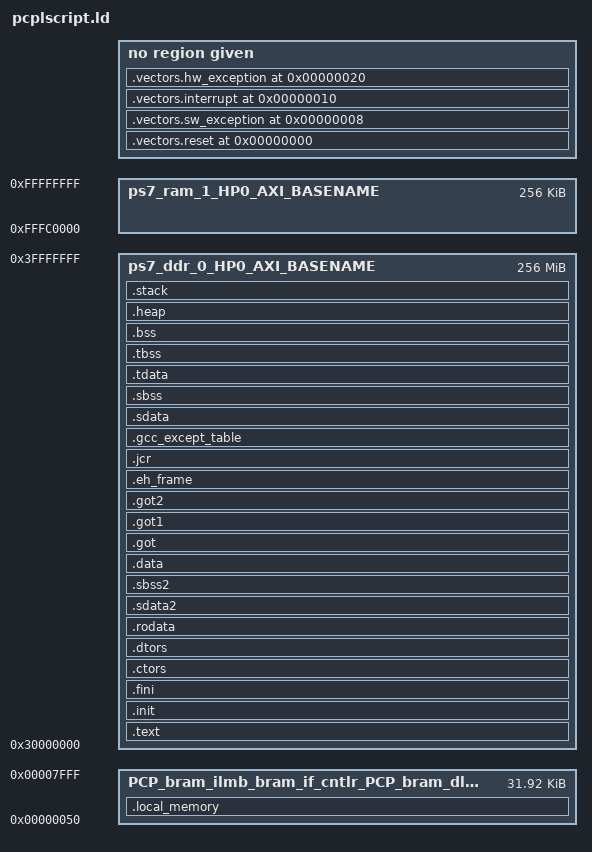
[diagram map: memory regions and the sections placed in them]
/*******************************************************************/
/*                                                                 */
/* This file is automatically generated by linker script generator.*/
/*                                                                 */
/* Version: Xilinx Software developement kit 2016.2                */
/*                                                                 */
/* Copyright (c) 2010-2016 Xilinx, Inc.  All rights reserved.      */
/*                                                                 */
/* Description : MicroBlaze Linker Script                          */
/*                                                                 */
/*******************************************************************/

_STACK_SIZE = DEFINED(_STACK_SIZE) ? _STACK_SIZE : 0xA00000;
_HEAP_SIZE = DEFINED(_HEAP_SIZE) ? _HEAP_SIZE : 0xA00000;

/* Define Memories in the system */

MEMORY
{
   PCP_bram_ilmb_bram_if_cntlr_PCP_bram_dlmb_bram_if_cntlr : ORIGIN = 0x50, LENGTH = 0x7FB0
   ps7_ddr_0_HP0_AXI_BASENAME : ORIGIN = 0x30000000, LENGTH = 0x10000000
   ps7_ram_1_HP0_AXI_BASENAME : ORIGIN = 0xFFFC0000, LENGTH = 0x40000
}

/* Specify the default entry point to the program */

ENTRY(_start)

/* Define the sections, and where they are mapped in memory */

SECTIONS
{
.vectors.reset 0x0 : {
   KEEP (*(.vectors.reset))
}

.vectors.sw_exception 0x8 : {
   KEEP (*(.vectors.sw_exception))
}

.vectors.interrupt 0x10 : {
   KEEP (*(.vectors.interrupt))
}

.vectors.hw_exception 0x20 : {
   KEEP (*(.vectors.hw_exception))
}

.text : {
   *(.text)
   *(.text.*)
   *(.gnu.linkonce.t.*)
} > ps7_ddr_0_HP0_AXI_BASENAME

.init : {
   KEEP (*(.init))
} > ps7_ddr_0_HP0_AXI_BASENAME

.fini : {
   KEEP (*(.fini))
} > ps7_ddr_0_HP0_AXI_BASENAME

.ctors : {
   __CTOR_LIST__ = .;
   ___CTORS_LIST___ = .;
   KEEP (*crtbegin.o(.ctors))
   KEEP (*(EXCLUDE_FILE(*crtend.o) .ctors))
   KEEP (*(SORT(.ctors.*)))
   KEEP (*(.ctors))
   __CTOR_END__ = .;
   ___CTORS_END___ = .;
} > ps7_ddr_0_HP0_AXI_BASENAME

.dtors : {
   __DTOR_LIST__ = .;
   ___DTORS_LIST___ = .;
   KEEP (*crtbegin.o(.dtors))
   KEEP (*(EXCLUDE_FILE(*crtend.o) .dtors))
   KEEP (*(SORT(.dtors.*)))
   KEEP (*(.dtors))
   PROVIDE(__DTOR_END__ = .);
   PROVIDE(___DTORS_END___ = .);
} > ps7_ddr_0_HP0_AXI_BASENAME

.rodata : {
   __rodata_start = .;
   *(.rodata)
   *(.rodata.*)
   *(.gnu.linkonce.r.*)
   __rodata_end = .;
} > ps7_ddr_0_HP0_AXI_BASENAME

.sdata2 : {
   . = ALIGN(8);
   __sdata2_start = .;
   *(.sdata2)
   *(.sdata2.*)
   *(.gnu.linkonce.s2.*)
   . = ALIGN(8);
   __sdata2_end = .;
} > ps7_ddr_0_HP0_AXI_BASENAME

.sbss2 : {
   __sbss2_start = .;
   *(.sbss2)
   *(.sbss2.*)
   *(.gnu.linkonce.sb2.*)
   __sbss2_end = .;
} > ps7_ddr_0_HP0_AXI_BASENAME

.data : {
   . = ALIGN(4);
   __data_start = .;
   *(.data)
   *(.data.*)
   *(.gnu.linkonce.d.*)
   __data_end = .;
} > ps7_ddr_0_HP0_AXI_BASENAME

.got : {
   *(.got)
} > ps7_ddr_0_HP0_AXI_BASENAME

.got1 : {
   *(.got1)
} > ps7_ddr_0_HP0_AXI_BASENAME

.got2 : {
   *(.got2)
} > ps7_ddr_0_HP0_AXI_BASENAME

.eh_frame : {
   *(.eh_frame)
} > ps7_ddr_0_HP0_AXI_BASENAME

.jcr : {
   *(.jcr)
} > ps7_ddr_0_HP0_AXI_BASENAME

.gcc_except_table : {
   *(.gcc_except_table)
} > ps7_ddr_0_HP0_AXI_BASENAME

.sdata : {
   . = ALIGN(8);
   __sdata_start = .;
   *(.sdata)
   *(.sdata.*)
   *(.gnu.linkonce.s.*)
   __sdata_end = .;
} > ps7_ddr_0_HP0_AXI_BASENAME

.sbss (NOLOAD) : {
   . = ALIGN(4);
   __sbss_start = .;
   *(.sbss)
   *(.sbss.*)
   *(.gnu.linkonce.sb.*)
   . = ALIGN(8);
   __sbss_end = .;
} > ps7_ddr_0_HP0_AXI_BASENAME

.tdata : {
   __tdata_start = .;
   *(.tdata)
   *(.tdata.*)
   *(.gnu.linkonce.td.*)
   __tdata_end = .;
} > ps7_ddr_0_HP0_AXI_BASENAME

.tbss : {
   __tbss_start = .;
   *(.tbss)
   *(.tbss.*)
   *(.gnu.linkonce.tb.*)
   __tbss_end = .;
} > ps7_ddr_0_HP0_AXI_BASENAME

.bss (NOLOAD) : {
   . = ALIGN(4);
   __bss_start = .;
   *(.bss)
   *(.bss.*)
   *(.gnu.linkonce.b.*)
   *(COMMON)
   . = ALIGN(4);
   __bss_end = .;
} > ps7_ddr_0_HP0_AXI_BASENAME

.local_memory : {
   __local_memory_start = .;
   *(.local_memory)
   __local_memory_end = .;
} > PCP_bram_ilmb_bram_if_cntlr_PCP_bram_dlmb_bram_if_cntlr

_SDA_BASE_ = __sdata_start + ((__sbss_end - __sdata_start) / 2 );

_SDA2_BASE_ = __sdata2_start + ((__sbss2_end - __sdata2_start) / 2 );

/* Generate Stack and Heap definitions */

.heap (NOLOAD) : {
   . = ALIGN(8);
   _heap = .;
   _heap_start = .;
   . += _HEAP_SIZE;
   _heap_end = .;
} > ps7_ddr_0_HP0_AXI_BASENAME

.stack (NOLOAD) : {
   _stack_end = .;
   . += _STACK_SIZE;
   . = ALIGN(8);
   _stack = .;
   __stack = _stack;
} > ps7_ddr_0_HP0_AXI_BASENAME

_end = .;
}
